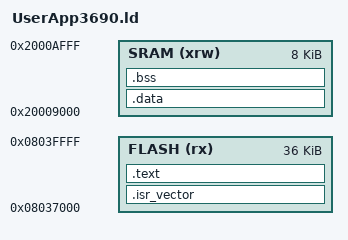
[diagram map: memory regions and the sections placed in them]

/* Memory Spaces Definitions */
MEMORY
{
/* change FLASH ORIGIN also change the the application's entry point address */
 	FLASH (rx) : ORIGIN = 0x08037000, LENGTH = 36K
/* change SRAM ORIGIN  */
	SRAM (xrw) : ORIGIN = 0x20009000, LENGTH = 8K
}


/* Sections Definitions */

SECTIONS
{
    PROVIDE(SysCallLib =  0x0800a14c);
	
	/* for Cortex devices, the beginning of the startup code is stored in the .isr_vector section, which goes to FLASH */
    .isr_vector :
    {
	. = ALIGN(4);
        KEEP(*(.isr_vector))            /* Startup code */
	. = ALIGN(4);
    } >FLASH
        
    /* the program code is stored in the .text section, which goes to Flash */
    .text :
    {
	    . = ALIGN(4);
	    
        *(.text)                   /* remaining code */
        *(.text.*)                   /* remaining code */
        *(.rodata)                 /* read-only data (constants) */
        *(.rodata*)

	    . = ALIGN(4);
   	 _etext = .;
	    /* This is used by the startup in order to initialize the .data secion */
   	 _sidata = _etext;
    } >FLASH
    
 
    /* This is the initialized data section
    The program executes knowing that the data is in the RAM
    but the loader puts the initial values in the FLASH (inidata).
    It is one task of the startup to copy the initial values from FLASH to RAM. */
    .data  : AT ( _sidata )
    {
	    . = ALIGN(4);
        /* This is used by the startup in order to initialize the .data secion */
        _sdata = . ;
        
        *(.data)
        *(.data.*)

	    . = ALIGN(4);
	    /* This is used by the startup in order to initialize the .data secion */
   	 _edata = . ;
    } >SRAM
    
    

    /* This is the uninitialized data section */
    .bss :
    {
	    . = ALIGN(4);
        /* This is used by the startup in order to initialize the .bss secion */
        _sbss = .;
        
        *(.bss)
        *(COMMON)
            . = ALIGN(4);
	    /* This is used by the startup in order to initialize the .bss secion */
   	 _ebss = . ;
    } >SRAM
    
    PROVIDE ( _end = _ebss );
   /*PROVIDE ( _sbrk = _ebss );*/
}
